# AFE0 register map
Vendor: Texas Instruments
Peripheral module from a debugger description file (folder UCD3138R064RSM).
Registers are 32-bit, read-write, no defined reset value unless marked. A register's access mark holds for its fields unless they carry their own. Offsets are as the file gives them; lines under a group give offsets from that group; [hi:lo] are bit positions; {n}, {i} and the like mark numbered series; 'fields as' and 'values as' point back to an identical list; <NAME> marks a mode.

## AFE0 — Top Module of AFE
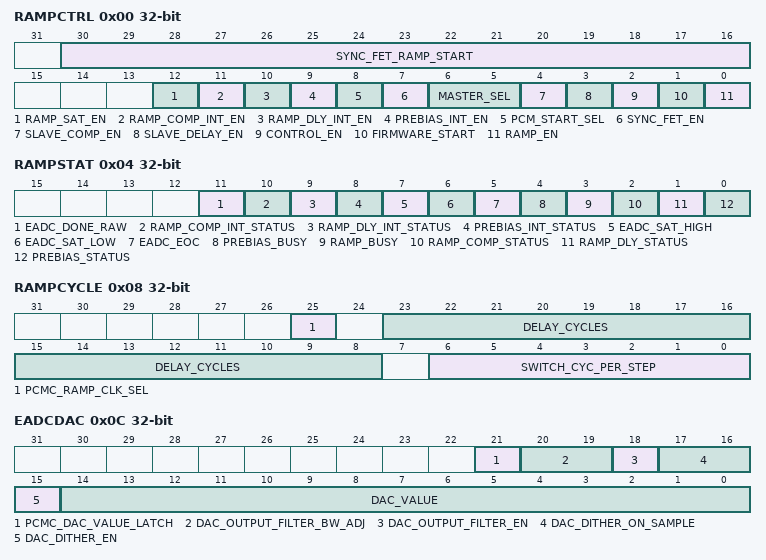
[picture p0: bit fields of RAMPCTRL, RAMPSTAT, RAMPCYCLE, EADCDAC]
0x00 RAMPCTRL access per field — Ramp Control Register
  [30:16] SYNC_FET_RAMP_START rw — Provides the starting value for the SyncFET Ramp with a resolution of High Frequency Oscillator Period/bit
  [12] RAMP_SAT_EN rw — Enables addition or subtraction of DAC Saturation Step when EADC is in saturation
    1=enabled (DAC Saturation Step logic is enabled, DAC incremented/decremented by value stored in DAC Saturation Step register when EADC is in saturation); 0=disabled (DAC Saturation Step logic is disabled, DAC incremented/decremented by value calculated by Ramp logic when EADC is in saturation (Default))
  [11] RAMP_COMP_INT_EN rw — Enables Ramp I/F Interrupt when soft-start/power-down ramp procedure is complete
    1=enabled (Soft-start/Power-Down Ramp Complete Interrupt is enabled); 0=disabled (Soft-start/Power-Down Ramp Complete Interrupt is disabled (Default))
  [10] RAMP_DLY_INT_EN rw — Enables Ramp I/F Interrupt when ramp delay procedure is complete
    1=enabled (Soft-start/Power-Down Ramp Delay Complete Interrupt is enabled); 0=disabled (Soft-start/Power-Down Ramp Delay Complete Interrupt is disabled (Default))
  [9] PREBIAS_INT_EN rw — Enables Ramp I/F Interrupt when Pre-Bias procedure is completed
    1=enabled (Pre-bias Complete Interrupt is enabled); 0=disabled (Pre-bias Complete Interrupt is disabled (Default))
  [8] PCM_START_SEL rw — Peak Current Mode Ramp Start Value Select
    1=PCM_FILTER_SEL (Ramp starts from filter output selected by PCM_FILTER_SEL bits in Loop Mux register PCMCTR); 0=DAC_VALUE (Ramp starts from value programmed in DAC_VALUE bits in EADC_DAC_VALUE Register (Default))
  [7] SYNC_FET_EN rw — Enables SyncFET Ramp Operation
    1=enabled (SyncFET Ramp Operation enabled); 0=disabled (SyncFET Ramp Operation disabled (Default))
  [6:5] MASTER_SEL rw — Selects Master Ramp I/F in slave mode
    2=FE_2 (Front End Control 2 acts as master); 1=FE_1 (Front End Control 1 acts as master); 0=FE_0 (Front End Control 0 acts as master (Default))
  [4] SLAVE_COMP_EN rw — Enables syncing of ramp start to Master Ramp I/F Complete pulse
    1=enabled (Ramp initiated by Master Ramp Complete pulse enabled); 0=disabled (Ramp initiated by Master Ramp Complete pulse disabled (Default))
  [3] SLAVE_DELAY_EN rw — Enables syncing of ramp start to Master Ramp I/F Delay Complete pulse
    1=enabled (Ramp initiated by Master Ramp Delay Complete pulse enabled); 0=disabled (Ramp initiated by Master Ramp Delay Complete pulse disabled (Default))
  [2] CONTROL_EN rw — Enables PMBus Control line to initiate ramp
    1=enabled (PMBus Control initiates ramp); 0=disabled (PMBus Control does not initiate ramp (Default))
  [1] FIRMWARE_START rw — Ramp start bit, self-clearing by ramp logic
    1=enabled (Ramp sequence initiated by firmware); 0=disabled (No ramp sequence initiated by firmware (Default))
  [0] RAMP_EN rw — Enable Ramp Logic (Pre-biasing should be disabled before asserting ramp, bit 16 of Pre-Bias Control Register)
    1=enabled (Enables hardware control of soft start or power-down ramp); 0=disabled (No soft start or power-down ramp controlled by hardware (Default))
0x04 RAMPSTAT ro — Ramp Status Register
  [11] EADC_DONE_RAW — EADC Conversion Done Raw Status
    1=COMPLETED (EADC Conversion has completed); 0=NOT_COMPLETED (EADC Conversion has not completed)
  [10] RAMP_COMP_INT_STATUS — EADC Conversion Done Raw Status
    1=COMPLETED (Ramp Delay Complete has been declared); 0=NOT_COMPLETED (No Ramp Delay Complete has been declared)
  [9] RAMP_DLY_INT_STATUS — Ramp Delay Complete latched status
    1=DECLARED (Ramp Delay Complete has been declared); 0=NOT_DECLARED (No Ramp Delay Complete has been declared)
  [8] PREBIAS_INT_STATUS — Pre-Bias Complete latched status
    1=DECLARED (Pre-Bias Complete has been declared); 0=NOT_DECLARED (No Pre-Bias Complete has been declared)
  [7] EADC_SAT_HIGH — EADC Saturation High Indicator
    1=SATURATED (EADC output is saturated at high limit); 0=NOT_SATURATED (EADC output is not saturated at high limit)
  [6] EADC_SAT_LOW — EADC Saturation Low Indicator
    1=SATURATED (EADC output is saturated at low limit); 0=NOT_SATURATED (EADC output is not saturated at low limit)
  [5] EADC_EOC — Indicates EADC end of conversion
  [4] PREBIAS_BUSY
    1=IN_PROGRESS (Pre-Bias in progress); 0=NO_PROGRESS (Pre-Bias is not in progress)
  [3] RAMP_BUSY
    1=IN_PROGRESS (Soft-Start/Power-Down Ramp is in progress); 0=NO_PROGRESS (Soft-Start/Power-Down Ramp is not in progress)
  [2] RAMP_COMP_STATUS — Ramp Complete, Raw Status
    1=COMPLETED (Ramp procedure is complete); 0=NOT_COMPLETED (Ramp procedure is not complete)
  [1] RAMP_DLY_STATUS — Ramp Delay Complete, Raw Status
    1=COMPLETED (Ramp delay procedure is complete); 0=NOT_COMPLETED (Ramp delay procedure is not complete)
  [0] PREBIAS_STATUS — Pre-Bias Complete, Raw Status
    1=COMPLETED (Pre-Bias is completed); 0=NOT_COMPLETED (Pre-Bias is not completed)
0x08 RAMPCYCLE access per field
  [25] PCMC_RAMP_CLK_SEL rw — Selects the clock for slope compensation ramp in PCMC mode
    1=ICLK (50MHz clock); 0=ICLK_BY_2 (25MHz clock)
  [23:8] DELAY_CYCLES rw — Configures the number of delay cycles before an initiation of ramp sequence. Each delay cycle consists of n switching cycles, as specified by SWITCH_CYC_PER_STEP (Bits 6-0). Number of delay cycles can vary from 0 to 65535
    2=two (Ramp starts after (2*SWITCH_CYC_PER_STEP) switching cycles); 1=one (Ramp starts after (1*SWITCH_CYC_PER_STEP) switching cycles); 0=NO_DELAY (Ramp starts without delay (Default))
  [6:0] SWITCH_CYC_PER_STEP rw — Selects number of switching cycles per DAC step. Number of subcycles can vary from 1 to 128
    2=two (3 subcycles per cycle); 1=one (2 subcycles per cycle); 0=NO_DELAY (1 switching cycle per step (Default))
0x0C EADCDAC — EADC DAC Value Register
  [21] PCMC_DAC_VALUE_LATCH — DAC_VALUE in DACSTAT latched at every peak current detect instant if EADC_MODE set to Peak current mode. Valid only for Peak current mode.
    1=enabled (DAC_VALUE latched at peak current detection); 0=disabled (DAC_VALUE not latched at peak current detection (Default))
  [20:19] DAC_OUTPUT_FILTER_BW_ADJ — DAC output filter bandwidth adjustment bits. Valid only if DAC_OUTPUT_FILTER_EN=1
    3=DAC_OUT_FILTER_10_KHZ (DAC output filter bandwidth is 10KHz); 2=DAC_OUT_FILTER_1_KHZ (DAC output filter bandwidth is 1KHz); 1=DAC_OUT_FILTER_ICLK_BY_320 (DAC output filter bandwidth is iclk by 320); 0=DAC_OUT_FILTER_ICLK_BY_160 (DAC output filter bandwidth is iclk by 160(Default))
  [18] DAC_OUTPUT_FILTER_EN — DAC output filter Enable
    1=enabled (DAC output filter enabled); 0=disabled (DAC output filter disabled (Default))
  [17:16] DAC_DITHER_ON_SAMPLE — DAC Dithering on based on Sample Trigger
    3=DAC_DITHER_ON_ICLK_BY_32 (DAC Dithering enabled at iclk/32); 2=DAC_DITHER_ON_ICLK_BY_16 (DAC Dithering enabled at iclk/16); 1=DAC_DITHER_ON_SAMPLE_ENABLE (DAC Dithering enabled on input sample trigger); 0=DAC_DITHER_ON_SAMPLE_DISABLE (DAC Dithering disabled on input sample trigger(Default))
  [15] DAC_DITHER_EN — DAC Dithering Enable
    1=enabled (DAC Dithering enabled); 0=disabled (DAC Dithering disabled (Default))
  [14:0] DAC_VALUE — Programmable DAC Value, effective LSB equals 0.09765625mV
0x10 RAMPDACEND — Ramp DAC Ending Value Register
  [14:0] RAMP_DAC_VALUE — Programmable DAC Value, effective LSB equals 0.09765625mV
0x14 DACSTEP
  [18:0] DAC_STEP — Programmable 19-bit unsigned DAC Step. Bits 18:10 represent the real portion of the DAC Step (0-511 DAC counts at bit resolution of 0.0625mV). Bits 9:0 represent the fractional portion of the DAC Step
0x18 DACSATSTEP — DAC Saturation Step Register
  [14:0] DAC_SAT_STEP — Programmable DAC Saturation Step, LSB equals 0.0625mV
    2=two (DAC adjusted by 2 DAC count on EADC saturation during ramp); 1=one (DAC adjusted by 1 DAC count on EADC saturation during ramp); 0=NO_ADJUST (DAC not adjusted on EADC saturation during ramp (Default))
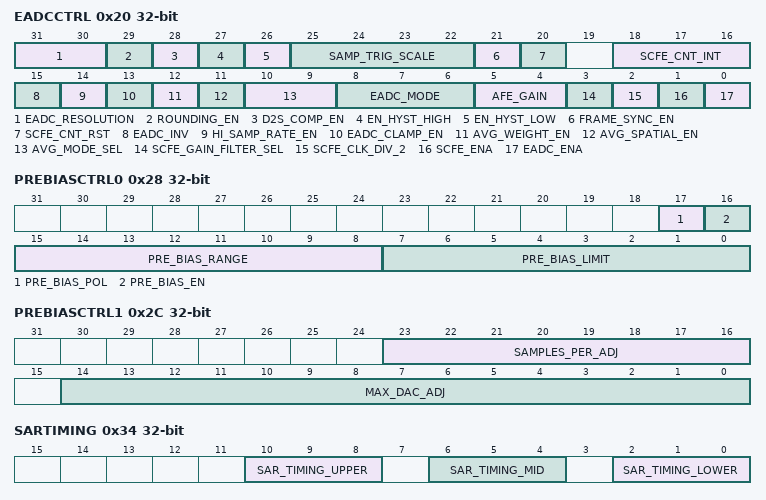
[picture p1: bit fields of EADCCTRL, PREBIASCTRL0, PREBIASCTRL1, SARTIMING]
0x20 EADCCTRL — EADC Control Register
  [31:30] EADC_RESOLUTION — error sensing resolution of eADC output
    3=mV_8 (8 mV resolution); 2=mV_4 (4 mV resolution); 1=mV_2 (2 mV resolution); 0=mV_1 (1 mV resolution (default))
  [29] ROUNDING_EN — Enables rounding of MSbs before dropping bits for lower resolution
    1=enabled (rounding enabled); 0=disabled (rounding disabled)
  [28] D2S_COMP_EN — Analog Front End Ramp Comparator Enable
    1=enabled (Analog Front End Ramp Comparator enabled); 0=disabled (Analog Front End Ramp Comparator disabled (Default))
  [27] EN_HYST_HIGH — Increase comparator trip point by ~70mV
    1=enabled (Enables increase of ramp comparator trip point); 0=disabled (Disables increase of ramp comparator trip point (Default))
  [26] EN_HYST_LOW — Decrease comparator trip point by ~70mV
    1=enabled (Enables decrease of ramp comparator trip point); 0=disabled (Disables decrease of ramp comparator trip point (Default))
  [25:22] SAMP_TRIG_SCALE — Provides capability to mask incoming sample triggers to Front End Control
    2=three (EADC conversion initiated once every 3 received sample triggers); 1=two (EADC conversion initiated once every 2 received sample triggers); 0=once (EADC conversion initiated on every received sample trigger (Default))
  [21] FRAME_SYNC_EN — Enable synchronization of switched cap front end counter to Switching Cycle Frame boundary
    1=SYNCHRONIZED (Switch Cap Front End Counter synchronized to frame boundary); 0=NOT_SYNCHRONIZED (Switch Cap Front End Counter not synchronized to frame (Default))
  [20] SCFE_CNT_RST — Force reset of Switched Cap Front End Counter
    1=RESET (Switch Cap Front End Counter reset); 0=OPERATIONAL (Switch Cap Front End Counter operational (Default))
  [18:16] SCFE_CNT_INT — Configures initial Switched Cap Front End Counter value out of reset or at start of switching cycle in Peak Current mode
  [15] EADC_INV — Enables EADC Data Inversion on data to filter module
    1=INVERTED (EADC Data Inverted); 0=NOT_INVERTED (EADC Data is not inverted (Default))
  [14] HI_SAMP_RATE_EN — Enables 50MSPS sampling rate
    1=MSPS_50 (50MSPS sampling rate); 0=MSPS_25 (25MSPS sampling rate)
  [13] EADC_CLAMP_EN — Enables or disables output clamping of EADC output
    1=enabled (Enable clamp); 0=disabled (Disable clamp (Default))
  [12] AVG_WEIGHT_EN — Enables weighted averaging in EADC averaging mode, only applicable in 4x and 8x averaging mode. For 4x averaging, two oldest samples are each weighted by 1/8, the next oldest sample has a weight of ¼ and the newest sample is weighted by ½. For 8x averaging, the four oldest samples are each weighted by 1/16, the next 2 oldest samples are weighted by 1/8, and the two newest samples are weighted by 1/4
    1=enabled (Weighted averaging enabled); 0=disabled (Weighted averaging disabled (Default))
  [11] AVG_SPATIAL_EN — Enables spatial mode in EADC averaging mode
    1=enabled (EADC samples averaged based on received sample triggers from DPWM modules. 2 sample triggers required for a single averaged sample to filter. 4 sample triggers required for a single averaged sample to filter module); 0=disabled (Consecutive EADC samples averaged based on every received sample trigger from DPWM modules (Default))
  [10:9] AVG_MODE_SEL — Averaging Mode Configuration
    2=x_8 (8x Averaging); 1=x_4 (4x Averaging); 0=x_2 (2x Averaging (Default))
  [8:6] EADC_MODE — Selects EADC Mode Operation
    7=CPCC_2 (Constant Power/Constant Current Control 2 Mode (CPCC module controls switching between Standard mode and Continuous SAR Mode)); 6=CPCC (= Constant Power/Constant Current Control Mode (CPCC module controls switching between Standard Mode and Non-Continuous SAR Mode)); 5=Peak Current Mode; 3=con_sar (Continuous SAR Mode); 2=non_con_sar (Non-continuous SAR Mode); 1=x_2 (Averaging Mode, configured by AVG_MODE_SEL); 0=sample (Standard mode, EADC samples based on sample triggers from DPWM module (Default))
  [5:4] AFE_GAIN — AFE Front End Gain Setting
    3=x__4 (4x Gain, 1mV/LSB); 2=x_4 (4x Gain, 1mV/LSB); 1=1x Gain, 4mV/LSB; 0=1x Gain, 4mV/LSB
  [3] SCFE_GAIN_FILTER_SEL — Switched Cap Noise Filter Enable
    1=enabled (Enables Switch Cap Noise Filter (Default)); 0=disabled (Disables Switch Cap Noise Filter)
  [2] SCFE_CLK_DIV_2 — Switched Cap Front End Clock Divider Select
    1=divide_1 (Switch Cap Period divide by 1 (Default 64 ns nominal sample period)); 0=divide_2 (Switch Cap Period divide by 2 (128 ns nominal sample period))
  [1] SCFE_ENA — Switch Cap Front Enable
    values as SCFE_GAIN_FILTER_SEL
  [0] EADC_ENA — EADC Enable
    1=enabled (Enables EADC (Default)); 0=disabled (Disables EADC)
0x28 PREBIASCTRL0 — Pre-Bias Control Register 0
  [17] PRE_BIAS_POL — Configures polarity of received error voltage
    1=enabled (Error equals Vin-Vref); 0=default (Error equals Vref-Vin (Default))
  [16] PRE_BIAS_EN — Enable Pre-Biasing of Error ADC (Ramp should be disabled during pre-biasing, bit 0 of Ramp Control Register)
    1=enabled (Pre-Biasing by hardware has been enabled); 0=disabled (Pre-Biasing has not been initiated (Default))
  [15:8] PRE_BIAS_RANGE — Sets the acceptable range around the zero error point. If Error ADC value stays in range for number of samples specified by PRE_BIAS_LIMIT (Bits 7:0), PREBIAS_STATUS (Bit 0 of Ramp Status Register) is enabled. Range will be +/- PRE_BIAS_RANGE around zero error point
  [7:0] PRE_BIAS_LIMIT — Sets the acceptable number of samples in which the Error ADC value stays in range before asserting PREBIAS_STATUS (Bit 0 of Ramp Status Register). Counter limit ranges from 0 to 255. If PREBIAS_STATUS is set, it will take PRE_BIAS_LIMIT samples outside of acceptable range before clearing PREBIAS_STATUS
0x2C PREBIASCTRL1 access per field — Pre-Bias Control Register 1
  [23:16] SAMPLES_PER_ADJ rw — Configures the number of EADC samples between Pre-Bias DAC setpoint adjustments.DAC Setpoint adjustment after n+1 EADC sample
    2=enabled_3 (DAC Setpoint adjustment after 3 EADC samples); 1=enabled (DAC Setpoint adjustment after2 EADC sample); 0=default (DAC Setpoint adjustment on each EADC sample)
  [14:0] MAX_DAC_ADJ rw — Configures the maximum DAC setpoint adjustment step
0x30 SARCTRL access per field — SAR Control Register
  [15:8] SAR_RANGE rw — Configures acceptable range of error values before declaring SAR completion
0x34 SARTIMING access per field — SAR Control Register
  [10:8] SAR_TIMING_UPPER rw — Configures timing for Bits 10:8 of DAC setpoint for SAR Algorithm
  [6:4] SAR_TIMING_MID rw — Configures timing for Bits 7:6 of DAC setpoint for SAR Algorithm
  [2:0] SAR_TIMING_LOWER rw — Configures timing for Bits 5:0 of DAC setpoint for SAR Algorithm
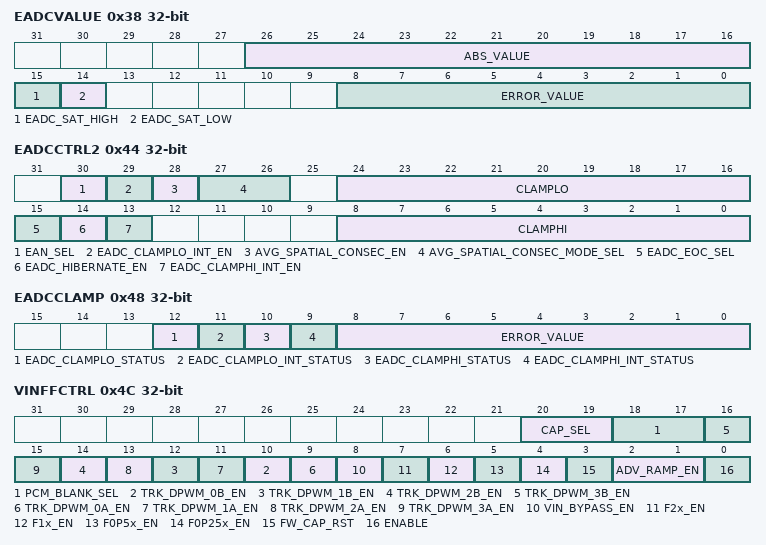
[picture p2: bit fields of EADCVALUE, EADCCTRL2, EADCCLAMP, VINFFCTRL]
0x38 EADCVALUE ro
  [26:16] ABS_VALUE — 10-bit Absolute Value calculated by Front End Control Module with a resolution of 1.5625mV/bit
  [15] EADC_SAT_HIGH — EADC Saturation High Indicator
    values as RAMPSTAT.EADC_SAT_HIGH
  [14] EADC_SAT_LOW — EADC Saturation low Indicator
    values as RAMPSTAT.EADC_SAT_LOW
  [8:0] ERROR_VALUE — Signed 9-bit Error value measured by Front End Control Module with a resolution of 1mV/bit
0x3C EADCRAWVALUE ro
  [8:0] RAW_ERROR_VALUE — Signed 9-bit Error value measured by Front End Control Module with a resolution of 1mV/bit. Value is raw EADC data before averaging.
0x40 DACSTAT ro — DAC Status Register
  [10:0] DAC_VALUE — Current 10-bit Value sent to DAC
0x44 EADCCTRL2 access per field — EADC Control Register 2
  [30] EAN_SEL rw — Default choice for EANx pin
  [29] EADC_CLAMPLO_INT_EN rw — EADC clamp low interrupt enable
  [28] AVG_SPATIAL_CONSEC_EN rw — Enables Spatial and Consecutive mode in EADC averaging mode
  [27:26] AVG_SPATIAL_CONSEC_MODE_SEL rw — Spatial Consecutive Averaging mode configuration
  [24:16] CLAMPLO rw — Low Clamp for 9bit eADC output (signed)
  [15] EADC_EOC_SEL rw — EADC end of conversion select
  [14] EADC_HIBERNATE_EN rw — EADC hibernate enable
  [13] EADC_CLAMPHI_INT_EN rw — EADC clamp high interrupt enable
  [8:0] CLAMPHI rw — High Clamp for 9bit eADC output (signed)
0x48 EADCCLAMP ro
  [12] EADC_CLAMPLO_STATUS — EADC Clamp low status
  [11] EADC_CLAMPLO_INT_STATUS — EADC Clamp low interrupt status
  [10] EADC_CLAMPHI_STATUS — EADC Clamp high status
  [9] EADC_CLAMPHI_INT_STATUS — EADC Clamp high interrupt status
  [8:0] ERROR_VALUE — Error value measured by Front End Control Module before clamping and inversion but after averaging and resolution control
0x4C VINFFCTRL — VINFF Control register
  [20:19] CAP_SEL — Programmable capacitor selections
  [18:17] PCM_BLANK_SEL — Selects blanking source as either of the PCMC modules
  [2n+10] TRK_DPWM_{n}B_EN (n=0..3) — Enable DPWM{n}B for tracking the input signal
  [2n+9] TRK_DPWM_{n}A_EN (n=0..3) — Enable DPWM{n}A for tracking the input signal
  [8] VIN_BYPASS_EN — Bypass VinFF block and conect input directly to output
  [7] F2x_EN — Enable 2x current branch
  [6] F1x_EN — Enable 1x current branch
  [5] F0P5x_EN — Enable 0.5x current branch
  [4] F0P25x_EN — Enable 0.25x current branch
  [3] FW_CAP_RST — Forcefully discharge ramp irrespective of anything else
  [2:1] ADV_RAMP_EN — Control the delay of ramp start
  [0] ENABLE — Enable VINFF Module
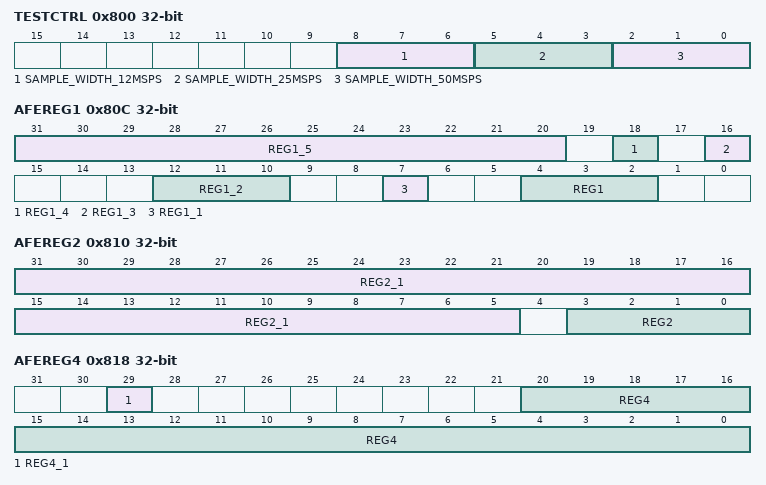
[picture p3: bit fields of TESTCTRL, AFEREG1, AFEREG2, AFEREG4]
0x800 TESTCTRL — Test Control Register (For Factory Test Use Only)
  [8:6] SAMPLE_WIDTH_12MSPS — Default eadc sampling signal pulse width for 12.5Msps
  [5:3] SAMPLE_WIDTH_25MSPS — Default eadc sampling signal pulse width for 25Msps
  [2:0] SAMPLE_WIDTH_50MSPS — Default eadc sampling signal pulse width for 50Msps
0x804 AFEDTB — AFE DTB Configuration register (For Factory Test Use Only)
  [2:0] SEL — AFE DTB mux select Bits
0x808 EADCTRIM — EADC Trim Register (For Factory Test Use Only)
  [31:0] TRIM — Register will be programmed during test and should not be overwritten by firmware
0x80C AFEREG1 access per field — AFE register 1 for analog (For Factory Test Use Only)
  [31:20] REG1_5 rw — Register will be programmed during test and should not be overwritten by firmware
  [18] REG1_4 rw — Register will be programmed during test and should not be overwritten by firmware
  [16] REG1_3 rw — Register will be programmed during test and should not be overwritten by firmware
  [12:10] REG1_2 rw — Register will be programmed during test and should not be overwritten by firmware
  [7] REG1_1 rw — Register will be programmed during test and should not be overwritten by firmware
  [4:2] REG1 rw — Register will be programmed during test and should not be overwritten by firmware
0x810 AFEREG2 access per field — AFE register 2 for analog (For Factory Test Use Only)
  [31:5] REG2_1 rw — Register will be programmed during test and should not be overwritten by firmware
  [3:0] REG2 rw — Register will be programmed during test and should not be overwritten by firmware
0x814 AFEREG3 — AFE register 3 for analog (For Factory Test Use Only)
  [31:0] REG3 — Register will be programmed during test and should not be overwritten by firmware
0x818 AFEREG4 access per field — AFE register 4 for analog (For Factory Test Use Only)
  [29] REG4_1 rw — Register will be programmed during test and should not be overwritten by firmware
  [20:0] REG4 rw — Register will be programmed during test and should not be overwritten by firmware
0x81C AFEREG5 — AFE register 5 for analog (For Factory Test Use Only)
  [31:0] REG5 — Register will be programmed during test and should not be overwritten by firmware
0x820 SPAREREG — Spare register for analog (For Factory Test Use Only)
  [31:0] SPARE — Register will be programmed during test and should not be overwritten by firmware
